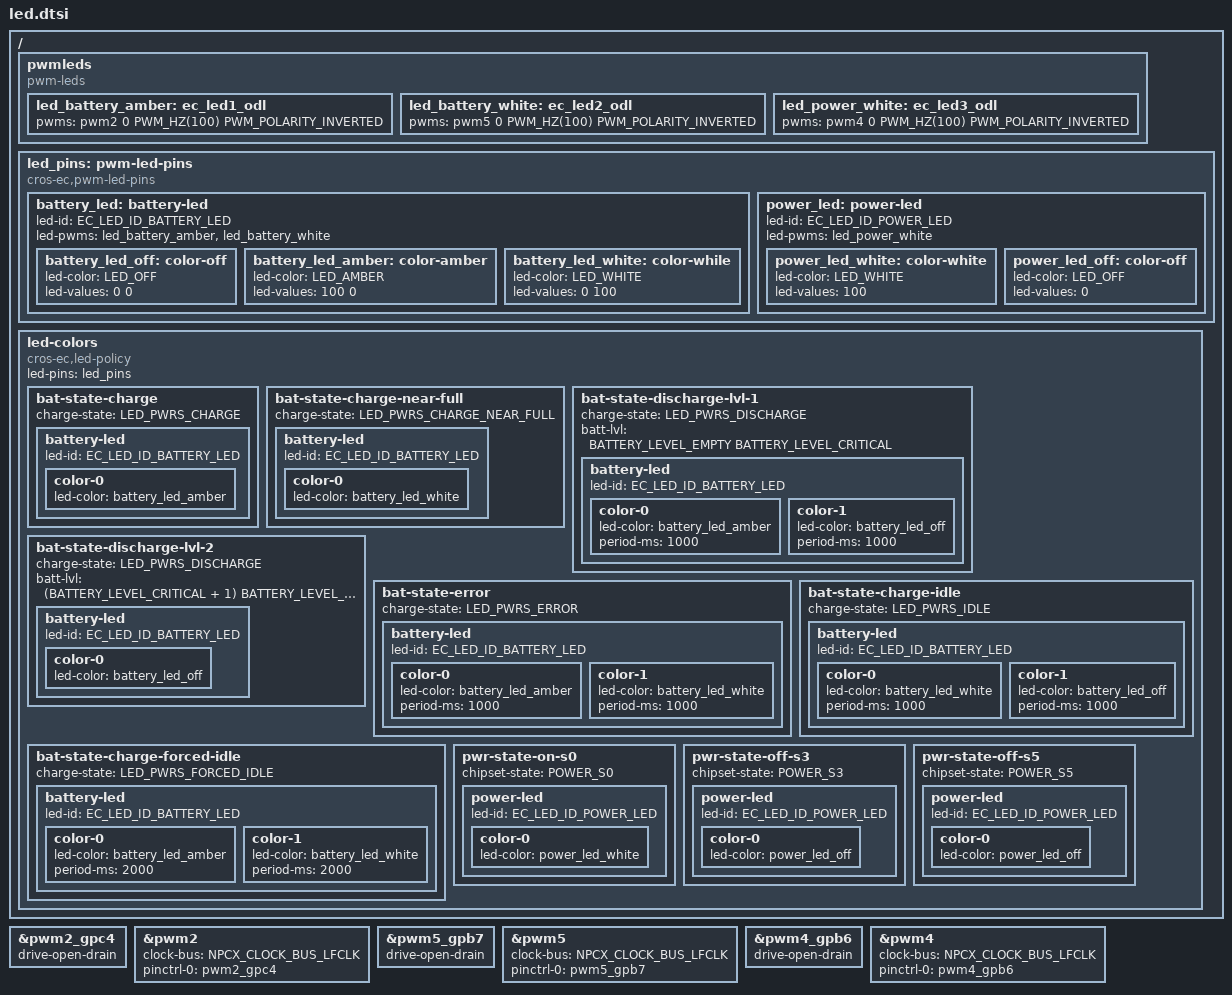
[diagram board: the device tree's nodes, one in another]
/* Copyright 2025 The ChromiumOS Authors
 * Use of this source code is governed by a BSD-style license that can be
 * found in the LICENSE file.
 */

 /* This file should only be included in the project.overlay. */
/ {
	pwmleds {
		compatible = "pwm-leds";
		led_battery_amber: ec_led1_odl {
			pwms = <&pwm2 0 PWM_HZ(100) PWM_POLARITY_INVERTED>;
		};
		led_battery_white: ec_led2_odl {
			pwms = <&pwm5 0 PWM_HZ(100) PWM_POLARITY_INVERTED>;
		};
		led_power_white: ec_led3_odl {
			pwms = <&pwm4 0 PWM_HZ(100) PWM_POLARITY_INVERTED>;
		};
	};

	led_pins: pwm-led-pins {
		compatible = "cros-ec,pwm-led-pins";

		battery_led: battery-led {
			led-id = "EC_LED_ID_BATTERY_LED";
			led-pwms = <&led_battery_amber &led_battery_white>;

			battery_led_off: color-off {
				led-color = "LED_OFF";
				led-values = <0 0>;
			};

			battery_led_amber: color-amber {
				led-color = "LED_AMBER";
				led-values = <100 0>;
			};

			battery_led_white: color-while {
				led-color = "LED_WHITE";
				led-values = <0 100>;
			};
		};

		power_led: power-led {
			led-id = "EC_LED_ID_POWER_LED";
			led-pwms = <&led_power_white>;

			power_led_white: color-white {
				led-color = "LED_WHITE";
				led-values = <100>;
			};

			power_led_off: color-off {
				led-color = "LED_OFF";
				led-values = <0>;
			};
		};
	};

	led-colors {
		compatible = "cros-ec,led-policy";
		led-pins = <&led_pins>;

		bat-state-charge {
			charge-state = "LED_PWRS_CHARGE";

			battery-led {
				led-id = "EC_LED_ID_BATTERY_LED";
				color-0 {
					led-color = <&battery_led_amber>;
				};
			};
		};

		bat-state-charge-near-full {
			charge-state = "LED_PWRS_CHARGE_NEAR_FULL";

			battery-led {
				led-id = "EC_LED_ID_BATTERY_LED";

				color-0 {
					led-color = <&battery_led_white>;
				};
			};
		};

		bat-state-discharge-lvl-1 {
			charge-state = "LED_PWRS_DISCHARGE";
			/* Battery percent range (<= 5%) */
			batt-lvl = <BATTERY_LEVEL_EMPTY BATTERY_LEVEL_CRITICAL>;

			battery-led {
				led-id = "EC_LED_ID_BATTERY_LED";

				color-0 {
					led-color = <&battery_led_amber>;
					period-ms = <1000>;
				};

				color-1 {
					led-color = <&battery_led_off>;
					period-ms = <1000>;
				};
			};
		};

		bat-state-discharge-lvl-2 {
			charge-state = "LED_PWRS_DISCHARGE";
			/* Battery percent range (>= 6%) */
			batt-lvl = <(BATTERY_LEVEL_CRITICAL + 1) BATTERY_LEVEL_FULL>;

			battery-led {
				led-id = "EC_LED_ID_BATTERY_LED";

				color-0 {
					led-color = <&battery_led_off>;
				};
			};
		};

		bat-state-error {
			charge-state = "LED_PWRS_ERROR";

			battery-led {
				led-id = "EC_LED_ID_BATTERY_LED";

				color-0 {
					led-color = <&battery_led_amber>;
					period-ms = <1000>;
				};

				color-1 {
					led-color = <&battery_led_white>;
					period-ms = <1000>;
				};
			};
		};

		bat-state-charge-idle {
			charge-state = "LED_PWRS_IDLE";

			battery-led {
				led-id = "EC_LED_ID_BATTERY_LED";

				color-0 {
					led-color = <&battery_led_white>;
					period-ms = <1000>;
				};

				color-1 {
					led-color = <&battery_led_off>;
					period-ms = <1000>;
				};
			};
		};

		bat-state-charge-forced-idle {
			charge-state = "LED_PWRS_FORCED_IDLE";

			battery-led {
				led-id = "EC_LED_ID_BATTERY_LED";

				color-0 {
					led-color = <&battery_led_amber>;
					period-ms = <2000>;
				};
				color-1 {
					led-color = <&battery_led_white>;
					period-ms = <2000>;
				};
			};
		};

		pwr-state-on-s0 {
			chipset-state = "POWER_S0";

			power-led {
				led-id = "EC_LED_ID_POWER_LED";
				color-0 {
					led-color = <&power_led_white>;
				};
			};
		};

		pwr-state-off-s3 {
			chipset-state = "POWER_S3";

			power-led {
				led-id = "EC_LED_ID_POWER_LED";
				color-0 {
					led-color = <&power_led_off>;
				};
			};
		};

		pwr-state-off-s5 {
			chipset-state = "POWER_S5";

			power-led {
				led-id = "EC_LED_ID_POWER_LED";
				color-0 {
					led-color = <&power_led_off>;
				};
			};
		};
	};
};

/* Battery Amber LED */
&pwm2_gpc4 {
	drive-open-drain;
};

&pwm2 {
	status = "okay";
	clock-bus = "NPCX_CLOCK_BUS_LFCLK";
	pinctrl-0 = <&pwm2_gpc4>;
	pinctrl-names = "default";
};

/* Battery Whlie LED */
&pwm5_gpb7 {
	drive-open-drain;
};

&pwm5 {
	status = "okay";
	clock-bus = "NPCX_CLOCK_BUS_LFCLK";
	pinctrl-0 = <&pwm5_gpb7>;
	pinctrl-names = "default";
};

/* Power White LED */
&pwm4_gpb6 {
	drive-open-drain;
};

&pwm4 {
	status = "okay";
	clock-bus = "NPCX_CLOCK_BUS_LFCLK";
	pinctrl-0 = <&pwm4_gpb6>;
	pinctrl-names = "default";
};
